AUTOSAR XML (schema 4-2-2)
package /ComponentTypes
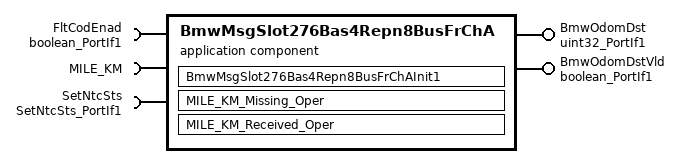
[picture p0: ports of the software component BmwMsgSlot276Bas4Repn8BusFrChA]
  application sw component type BmwMsgSlot276Bas4Repn8BusFrChA
    provide port BmwOdomDst: nonqueued-sender-com-spec{data-element=Val, init-value=0}, provided-interface=uint32_PortIf1
    provide port BmwOdomDstVld: nonqueued-sender-com-spec{data-element=Logl, init-value=0}, provided-interface=boolean_PortIf1
    require port FltCodEnad: nonqueued-receiver-com-spec{data-element=Logl, filter=data-filter-type=ALWAYS, init-value=1}, required-interface=boolean_PortIf1
    require port MILE_KM: nonqueued-receiver-com-spec{data-element=MILE_KM, alive-timeout=11, filter=data-filter-type=ALWAYS, init-value=0}, required-interface=MILE_KM
    require port SetNtcSts: client-com-spec=Oper, required-interface=SetNtcSts_PortIf1
    behavior BmwMsgSlot276Bas4Repn8BusFrChA_InternalBehavior
      ar-typed-per-instance-memorys:
        5 x data, all with sw-calibration-access=READ-ONLY:
          BmwOdomDstPrev: type=uint32
          KiloMtrStandFaildCnt: type=uint8
          KiloMtrStandPassdCnt: type=uint8
          MissingMsgCnt: type=uint8
          RxMsgCnt: type=uint8
      init event BmwMsgSlot276Bas4Repn8BusFrChA_InitEvent: start-on-event=BmwMsgSlot276Bas4Repn8BusFrChAInit1
      data receive error event DRET_MILE_KM_Missing_Oper_MILE_KM_MILE_KM: start-on-event=MILE_KM_Missing_Oper, data=MILE_KM.MILE_KM
      data received event DRT_MILE_KM_Received_Oper_MILE_KM_MILE_KM: start-on-event=MILE_KM_Received_Oper, data=MILE_KM.MILE_KM
      port-api-options:
        enable-take-address=false, error-handling=NO-TRANSFORMER-ERROR-HANDLING, indirect-api=false, port=BmwOdomDst
        enable-take-address=false, error-handling=NO-TRANSFORMER-ERROR-HANDLING, indirect-api=false, port=BmwOdomDstVld
        enable-take-address=false, error-handling=NO-TRANSFORMER-ERROR-HANDLING, indirect-api=false, port=MILE_KM
        enable-take-address=false, error-handling=NO-TRANSFORMER-ERROR-HANDLING, indirect-api=false, port=SetNtcSts
      runnable BmwMsgSlot276Bas4Repn8BusFrChAInit1
        data-receive-point-by-arguments:
          access REC_FltCodEnad_Logl: accessed-variable=FltCodEnad.Logl
          access REC_MILE_KM_MILE_KM: accessed-variable=MILE_KM.MILE_KM
        data-send-points:
          access SEND_BmwOdomDst_Val: accessed-variable=BmwOdomDst.Val
          access SEND_BmwOdomDstVld_Logl: accessed-variable=BmwOdomDstVld.Logl
        sync call SC_SetNtcSts_Oper: operation=SetNtcSts.Oper, timeout=0
      runnable MILE_KM_Missing_Oper
        data-receive-point-by-arguments:
          access REC_FltCodEnad_Logl: accessed-variable=FltCodEnad.Logl
          access REC_MILE_KM_MILE_KM: accessed-variable=MILE_KM.MILE_KM
        data-send-points:
          access SEND_BmwOdomDst_Val: accessed-variable=BmwOdomDst.Val
          access SEND_BmwOdomDstVld_Logl: accessed-variable=BmwOdomDstVld.Logl
        sync call SC_SetNtcSts_Oper: operation=SetNtcSts.Oper, timeout=0
      runnable MILE_KM_Received_Oper
        data-receive-point-by-arguments:
          access REC_FltCodEnad_Logl: accessed-variable=FltCodEnad.Logl
          access REC_MILE_KM_MILE_KM: accessed-variable=MILE_KM.MILE_KM
        data-send-points:
          access SEND_BmwOdomDst_Val: accessed-variable=BmwOdomDst.Val
          access SEND_BmwOdomDstVld_Logl: accessed-variable=BmwOdomDstVld.Logl
        sync call SC_SetNtcSts_Oper: operation=SetNtcSts.Oper, timeout=0
  swc implementation BmwMsgSlot276Bas4Repn8BusFrChA_Implementation: behavior=BmwMsgSlot276Bas4Repn8BusFrChA_InternalBehavior
    code-descriptors:
      code Default: artifact-descriptors=autosar-engineering-object={short-label=Default, category=SWSRC}
